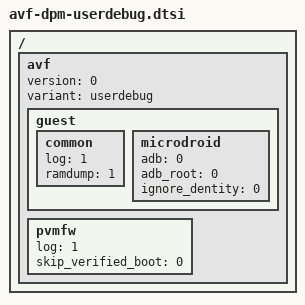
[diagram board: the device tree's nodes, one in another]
// SPDX-License-Identifier: GPL-2.0-only
/*
 * Android Virtualization Framework Debug Policy device tree source
 *
 * Copyright 2022 Google Inc.
 *
 * This program is free software; you can redistribute it and/or modify
 * it under the terms of the GNU General Public License version 2 as
 * published by the Free Software Foundation.
 */

/ {
	fragment@avf {
		target-path = "/";

		__overlay__ {
			avf {
				version = <0>;
				variant = "userdebug";
				guest {
					common {
						log = <1>;
						ramdump = <1>;
					};

					microdroid {
						adb = <0>;
						adb_root = <0>;
						ignore_dentity = <0>;
					};
				};

				pvmfw {
					log = <1>;
					skip_verified_boot = <0>;
				};
			};
		};
	};
}; /* end of avf */
